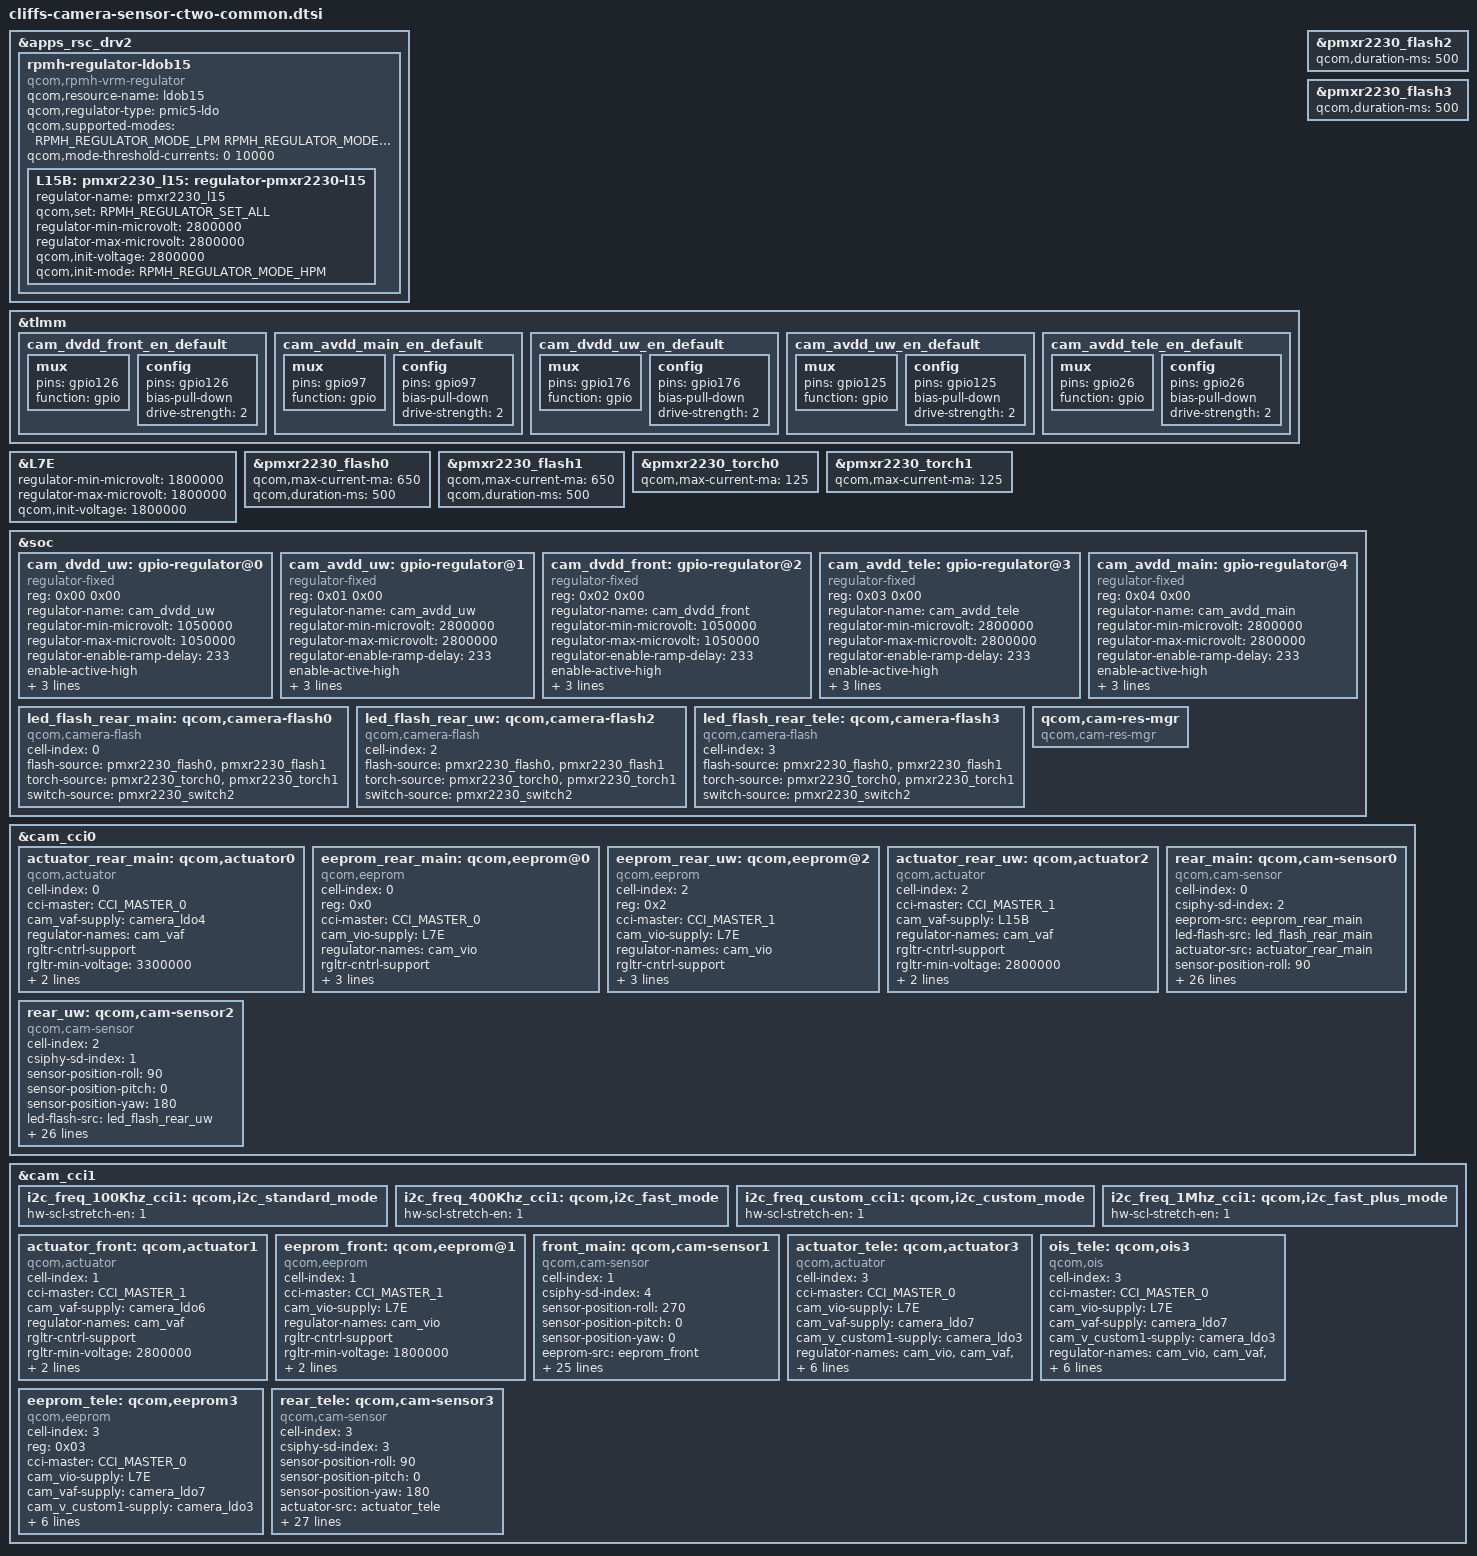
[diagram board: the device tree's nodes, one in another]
#include <dt-bindings/msm-camera.h>
#include <dt-bindings/regulator/qcom,rpmh-regulator-levels.h>

&apps_rsc_drv2 {
	rpmh-regulator-ldob15 {
		compatible = "qcom,rpmh-vrm-regulator";
		qcom,resource-name = "ldob15";
		qcom,regulator-type = "pmic5-ldo";
		qcom,supported-modes =
			<RPMH_REGULATOR_MODE_LPM
			RPMH_REGULATOR_MODE_HPM>;
		qcom,mode-threshold-currents = <0 10000>;

		L15B:
		pmxr2230_l15: regulator-pmxr2230-l15 {
			regulator-name = "pmxr2230_l15";
			qcom,set = <RPMH_REGULATOR_SET_ALL>;
			regulator-min-microvolt = <2800000>;
			regulator-max-microvolt = <2800000>;
			qcom,init-voltage = <2800000>;
			qcom,init-mode = <RPMH_REGULATOR_MODE_HPM>;
		};
	};
};

&tlmm {
	cam_dvdd_front_en_default: cam_dvdd_front_en_default {
		mux {
			pins = "gpio126";
			function = "gpio";
		};

		config {
			pins = "gpio126";
			bias-pull-down; /* PULL DOWN */
			drive-strength = <2>; /* 2 MA */
		};
	};

	cam_avdd_main_en_default: cam_avdd_main_en_default {
		mux {
			pins = "gpio97";
			function = "gpio";
		};

		config {
			pins = "gpio97";
			bias-pull-down; /* PULL DOWN */
			drive-strength = <2>; /* 2 MA */
		};
	};

	cam_dvdd_uw_en_default: cam_dvdd_uw_en_default {
		mux {
			pins = "gpio176";
			function = "gpio";
		};

		config {
			pins = "gpio176";
			bias-pull-down; /* PULL DOWN */
			drive-strength = <2>; /* 2 MA */
		};
	};

	cam_avdd_uw_en_default: cam_avdd_uw_en_default {
		mux {
			pins = "gpio125";
			function = "gpio";
		};

		config {
			pins = "gpio125";
			bias-pull-down; /* PULL DOWN */
			drive-strength = <2>; /* 2 MA */
		};
	};

	cam_avdd_tele_en_default: cam_avdd_tele_en_default {
		mux {
			pins = "gpio26";
			function = "gpio";
		};

		config {
			pins = "gpio26";
			bias-pull-down; /* PULL DOWN */
			drive-strength = <2>; /* 2 MA */
		};
	};

	//IOVDD for RON FVC
	//cam_iovdd_en_default: cam_iovdd_en_default {
	//	mux {
	//		pins = "gpio7";
	//		function = "gpio";
	//	};
	//
	//	config {
	//		pins = "gpio7";
	//		bias-pull-down; /* PULL DOWN */
	//		drive-strength = <2>; /* 2 MA */
	//	};
	//};

	//UW AFVDD for RON FVC
	//cam_afvdd_uw_en_default: cam_afvdd_uw_en_default {
	//	mux {
	//		pins = "gpio136";
	//		function = "gpio";
	//	};
	//
	//	config {
	//		pins = "gpio136";
	//		bias-pull-down; /* PULL DOWN */
	//		drive-strength = <2>; /* 2 MA */
	//	};
	//};
};

&L7E {
	regulator-min-microvolt = <1800000>;
	regulator-max-microvolt = <1800000>;
	qcom,init-voltage = <1800000>;
};

&pmxr2230_flash0 {
	qcom,max-current-ma = <650>;
	qcom,duration-ms = <500>;
};
&pmxr2230_flash1 {
	qcom,max-current-ma = <650>;
	qcom,duration-ms = <500>;
};
&pmxr2230_flash2 {
	qcom,duration-ms = <500>;
};
&pmxr2230_flash3 {
	qcom,duration-ms = <500>;
};

&pmxr2230_torch0 {
	qcom,max-current-ma = <125>;
};

&pmxr2230_torch1 {
	qcom,max-current-ma = <125>;
};

&soc {
	cam_dvdd_uw: gpio-regulator@0 {
		compatible = "regulator-fixed";
		reg = <0x00 0x00>;
		regulator-name = "cam_dvdd_uw";
		regulator-min-microvolt = <1050000>;
		regulator-max-microvolt = <1050000>;
		regulator-enable-ramp-delay = <233>;
		enable-active-high;
		gpio = <&tlmm 176 0>;
		pinctrl-names = "default";
		pinctrl-0 = <&cam_dvdd_uw_en_default>;
		vin-supply = <&S2B>;
	};

	cam_avdd_uw: gpio-regulator@1 {
		compatible = "regulator-fixed";
		reg = <0x01 0x00>;
		regulator-name = "cam_avdd_uw";
		regulator-min-microvolt = <2800000>;
		regulator-max-microvolt = <2800000>;
		regulator-enable-ramp-delay = <233>;
		enable-active-high;
		gpio = <&tlmm 125 0>;
		pinctrl-names = "default";
		pinctrl-0 = <&cam_avdd_uw_en_default>;
		vin-supply = <&BOB>;
	};

	cam_dvdd_front: gpio-regulator@2 {
		compatible = "regulator-fixed";
		reg = <0x02 0x00>;
		regulator-name = "cam_dvdd_front";
		regulator-min-microvolt = <1050000>;
		regulator-max-microvolt = <1050000>;
		regulator-enable-ramp-delay = <233>;
		enable-active-high;
		gpio = <&tlmm 126 0>;
		pinctrl-names = "default";
		pinctrl-0 = <&cam_dvdd_front_en_default>;
		vin-supply = <&S2B>;
	};

	cam_avdd_tele: gpio-regulator@3 {
		compatible = "regulator-fixed";
		reg = <0x03 0x00>;
		regulator-name = "cam_avdd_tele";
		regulator-min-microvolt = <2800000>;
		regulator-max-microvolt = <2800000>;
		regulator-enable-ramp-delay = <233>;
		enable-active-high;
		gpio = <&tlmm 26 0>;
		pinctrl-names = "default";
		pinctrl-0 = <&cam_avdd_tele_en_default>;
		vin-supply = <&BOB>;
	};

	cam_avdd_main: gpio-regulator@4 {
		compatible = "regulator-fixed";
		reg = <0x04 0x00>;
		regulator-name = "cam_avdd_main";
		regulator-min-microvolt = <2800000>;
		regulator-max-microvolt = <2800000>;
		regulator-enable-ramp-delay = <233>;
		enable-active-high;
		gpio = <&tlmm 97 0>;
		pinctrl-names = "default";
		pinctrl-0 = <&cam_avdd_main_en_default>;
		vin-supply = <&BOB>;
	};

/*
	//UW AFVDD for RON FVC
	cam_afvdd_uw: gpio-regulator@5 {
		compatible = "regulator-fixed";
		reg = <0x05 0x00>;
		regulator-name = "cam_afvdd_uw";
		regulator-min-microvolt = <2800000>;
		regulator-max-microvolt = <2800000>;
		regulator-enable-ramp-delay = <233>;
		enable-active-high;
		gpio = <&tlmm 136 0>;
		pinctrl-names = "default";
		pinctrl-0 = <&cam_afvdd_uw_en_default>;
		vin-supply = <&BOB>;
	};

	//IOVDD for RON FVC
	cam_iovdd: gpio-regulator@6 {
		compatible = "regulator-fixed";
		reg = <0x06 0x00>;
		regulator-name = "cam_iovdd";
		regulator-min-microvolt = <1800000>;
		regulator-max-microvolt = <1800000>;
		regulator-enable-ramp-delay = <233>;
		enable-active-high;
		gpio = <&tlmm 7 0>;
		pinctrl-names = "default";
		pinctrl-0 = <&cam_iovdd_en_default>;
		vin-supply = <&S1B>;
	};
*/

	led_flash_rear_main: qcom,camera-flash0 {
		cell-index = <0>;
		compatible = "qcom,camera-flash";
		flash-source = <&pmxr2230_flash0 &pmxr2230_flash1>;
		torch-source = <&pmxr2230_torch0 &pmxr2230_torch1>;
		switch-source = <&pmxr2230_switch2>;
		status = "ok";
	};

	led_flash_rear_uw: qcom,camera-flash2 {
		cell-index = <2>;
		compatible = "qcom,camera-flash";
		flash-source = <&pmxr2230_flash0 &pmxr2230_flash1>;
		torch-source = <&pmxr2230_torch0 &pmxr2230_torch1>;
		switch-source = <&pmxr2230_switch2>;
		status = "ok";
	};

	led_flash_rear_tele: qcom,camera-flash3 {
		cell-index = <3>;
		compatible = "qcom,camera-flash";
		flash-source = <&pmxr2230_flash0 &pmxr2230_flash1>;
		torch-source = <&pmxr2230_torch0 &pmxr2230_torch1>;
		switch-source = <&pmxr2230_switch2>;
		status = "ok";
	};

	qcom,cam-res-mgr {
		compatible = "qcom,cam-res-mgr";
		status = "ok";
	};
};

&cam_cci0 {
	actuator_rear_main: qcom,actuator0{
		cell-index = <0>;
		compatible = "qcom,actuator";
		cci-master = <CCI_MASTER_0>;
		cam_vaf-supply = <&camera_ldo4>;
		regulator-names = "cam_vaf";
		rgltr-cntrl-support;
		rgltr-min-voltage = <3300000>;
		rgltr-max-voltage = <3304000>;
		rgltr-load-current = <119000>;
		status = "ok";
	};

	eeprom_rear_main: qcom,eeprom@0 {
		cell-index = <0>;
		reg = <0x0>;
		compatible = "qcom,eeprom";
		cci-master = <CCI_MASTER_0>;
		cam_vio-supply = <&L7E>;
		regulator-names = "cam_vio";
		rgltr-cntrl-support;
		rgltr-min-voltage = <1800000>;
		rgltr-max-voltage = <1800000>;
		rgltr-load-current = <0>;
		status = "ok";
	};

 	eeprom_rear_uw: qcom,eeprom@2 {
		cell-index = <2>;
		reg = <0x2>;
		compatible = "qcom,eeprom";
		cci-master = <CCI_MASTER_1>;
		cam_vio-supply = <&L7E>;
		regulator-names = "cam_vio";
		rgltr-cntrl-support;
		rgltr-min-voltage = <1800000>;
		rgltr-max-voltage = <1800000>;
		rgltr-load-current = <0>;
		status = "ok";
	};

	actuator_rear_uw: qcom,actuator2{
		cell-index = <2>;
		compatible = "qcom,actuator";
		cci-master = <CCI_MASTER_1>;
		cam_vaf-supply = <&L15B>;
		regulator-names = "cam_vaf";
		rgltr-cntrl-support;
		rgltr-min-voltage = <2800000>;
		rgltr-max-voltage = <2800000>;
		rgltr-load-current = <147000>;
		status = "ok";
	};

	rear_main: qcom,cam-sensor0 {
		cell-index = <0>;
		compatible = "qcom,cam-sensor";
		csiphy-sd-index = <2>;
		eeprom-src = <&eeprom_rear_main>;
		led-flash-src = <&led_flash_rear_main>;
		actuator-src = <&actuator_rear_main>;
		sensor-position-roll = <90>;
		sensor-position-pitch = <0>;
		sensor-position-yaw = <180>;
		cam_vio-supply = <&L7E>;
		cam_vdig-supply = <&camera_ldo1>;
		cam_clk-supply = <&cam_cc_titan_top_gdsc>;
		cam_vana-supply = <&cam_avdd_main>;
		regulator-names = "cam_vana",
			"cam_vdig","cam_clk","cam_vio";
		rgltr-cntrl-support;
		rgltr-min-voltage = <2800000 1200000 0 1800000>;
		rgltr-max-voltage = <2800000 1200000 0 1800000>;
		rgltr-load-current = <101000 787000 0 1000>;
		gpio-no-mux = <0>;
		pinctrl-names = "cam_default", "cam_suspend";
		pinctrl-0 = <&cam_sensor_mclk0_active
			&cam_sensor_active_rst0>;
		pinctrl-1 = <&cam_sensor_mclk0_suspend
			&cam_sensor_suspend_rst0>;
		gpios = <&tlmm 64 0>,
			<&tlmm 15 0>;
		gpio-reset = <1>;
		gpio-req-tbl-num = <0 1>;
		gpio-req-tbl-flags = <1 0>;
		gpio-req-tbl-label = "CAMIF_MCLK0",
					"CAM_RESET0";
		cci-master = <CCI_MASTER_0>;
		clocks = <&camcc CAM_CC_MCLK0_CLK>;
		clock-names = "cam_clk";
		clock-cntl-level = "nominal";
		clock-rates = <19200000>;
		status = "ok";
	};

	rear_uw:qcom,cam-sensor2 {
		cell-index = <2>;
		compatible = "qcom,cam-sensor";
		csiphy-sd-index = <1>;
		sensor-position-roll = <90>;
		sensor-position-pitch = <0>;
		sensor-position-yaw = <180>;
		led-flash-src = <&led_flash_rear_uw>;
		eeprom-src = <&eeprom_rear_uw>;
		actuator-src = <&actuator_rear_uw>;
		cam_vio-supply = <&L7E>;
		cam_vdig-supply = <&cam_dvdd_uw>;
		cam_clk-supply = <&cam_cc_titan_top_gdsc>;
		cam_vana-supply = <&cam_avdd_uw>;
		regulator-names = "cam_vana",
			"cam_vdig", "cam_clk","cam_vio";
		rgltr-cntrl-support;
		rgltr-min-voltage = <2800000 1050000 0 1800000>;
		rgltr-max-voltage = <2800000 1050000 0 1800000>;
		rgltr-load-current = <148000 212000 0 3000>;
		gpio-no-mux = <0>;
		pinctrl-names = "cam_default", "cam_suspend";
		pinctrl-0 = <&cam_sensor_mclk1_active
				 &cam_sensor_active_rst1>;
		pinctrl-1 = <&cam_sensor_mclk1_suspend
				 &cam_sensor_suspend_rst1>;
		gpios = <&tlmm 65 0>,
			<&tlmm 14 0>;
		gpio-reset = <1>;
		gpio-req-tbl-num = <0 1>;
		gpio-req-tbl-flags = <1 0>;
		gpio-req-tbl-label = "CAMIF_MCLK1",
					"CAM_RESET1";
		cci-master = <CCI_MASTER_1>;
		clocks = <&camcc CAM_CC_MCLK1_CLK>;
		clock-names = "cam_clk";
		clock-cntl-level = "nominal";
		clock-rates = <24000000>;
		status = "ok";
	};
};

&cam_cci1 {
	i2c_freq_100Khz_cci1: qcom,i2c_standard_mode {
		hw-scl-stretch-en = <1>;
	};

	i2c_freq_400Khz_cci1: qcom,i2c_fast_mode {
		hw-scl-stretch-en = <1>;
	};

	i2c_freq_custom_cci1: qcom,i2c_custom_mode {
		hw-scl-stretch-en = <1>;
	};

	i2c_freq_1Mhz_cci1: qcom,i2c_fast_plus_mode {
		hw-scl-stretch-en = <1>;
	};

	actuator_front: qcom,actuator1{
		cell-index = <1>;
		compatible = "qcom,actuator";
		cci-master = <CCI_MASTER_1>;
		cam_vaf-supply = <&camera_ldo6>;
		regulator-names = "cam_vaf";
		rgltr-cntrl-support;
		rgltr-min-voltage = <2800000>;
		rgltr-max-voltage = <2800000>;
		rgltr-load-current = <95000>;
		status = "ok";
	};

	eeprom_front: qcom,eeprom@1 {
		cell-index = <1>;
		compatible = "qcom,eeprom";
		cci-master = <CCI_MASTER_1>;
		cam_vio-supply = <&L7E>;
		regulator-names = "cam_vio";
		rgltr-cntrl-support;
		rgltr-min-voltage = <1800000>;
		rgltr-max-voltage = <1800000>;
		rgltr-load-current = <3000>;
		status = "ok";
	};

	front_main: qcom,cam-sensor1 {
		cell-index = <1>;
		compatible = "qcom,cam-sensor";
		csiphy-sd-index = <4>;
		sensor-position-roll  = <270>;
		sensor-position-pitch = <0>;
		sensor-position-yaw   = <0>;
		eeprom-src = <&eeprom_front>;
		actuator-src = <&actuator_front>;
		cam_vio-supply  = <&L7E>;
		cam_vdig-supply = <&cam_dvdd_front>;
		cam_clk-supply  = <&cam_cc_titan_top_gdsc>;
		cam_vana-supply = <&camera_ldo5>;
		regulator-names = "cam_vdig", "cam_clk", "cam_vana","cam_vio";
		rgltr-cntrl-support;
		rgltr-min-voltage  = <1050000 0 2800000 1800000>;
		rgltr-max-voltage  = <1050000 0 2800000 1800000>;
		rgltr-load-current = <125000  0 95000   3000>;
		gpio-no-mux = <0>;
		pinctrl-names = "cam_default", "cam_suspend";
		pinctrl-0 = <&cam_sensor_mclk3_active &cam_sensor_active_rst3>;
		pinctrl-1 = <&cam_sensor_mclk3_suspend &cam_sensor_suspend_rst3>;
		gpios = <&tlmm 67 0>, <&tlmm 13 0>;
		gpio-reset = <1>;
		gpio-req-tbl-num   = <0 1>;
		gpio-req-tbl-flags = <1 0>;
		gpio-req-tbl-label = "CAMIF_MCLK3", "CAM_RESET3";
		cci-master = <CCI_MASTER_1>;
		clocks = <&camcc CAM_CC_MCLK3_CLK>;
		clock-names = "cam_clk";
		clock-cntl-level = "nominal";
		clock-rates = <24000000>;
		status = "ok";
	};

	actuator_tele: qcom,actuator3{
		cell-index = <3>;
		compatible = "qcom,actuator";
		cci-master = <CCI_MASTER_0>;
		cam_vio-supply = <&L7E>;
		cam_vaf-supply = <&camera_ldo7>;
		cam_v_custom1-supply = <&camera_ldo3>;
		regulator-names = "cam_vio", "cam_vaf", "cam_v_custom1";
		rgltr-cntrl-support;
		rgltr-min-voltage = <1800000 2800000 2800000>;
		rgltr-max-voltage = <1800000 2804000 2804000>;
		rgltr-load-current = <1000 227000 20000>;
		af-ois-use-same-ic;
		status = "ok";
	};

	ois_tele: qcom,ois3 {
		cell-index = <3>;
		compatible = "qcom,ois";
		cci-master = <CCI_MASTER_0>;
		cam_vio-supply = <&L7E>;
		cam_vaf-supply = <&camera_ldo7>;
		cam_v_custom1-supply  = <&camera_ldo3>;
		regulator-names = "cam_vio", "cam_vaf", "cam_v_custom1";
		rgltr-cntrl-support;
		rgltr-min-voltage = <1800000 2800000 2800000>;
		rgltr-max-voltage = <1800000 2804000 2804000>;
		rgltr-load-current = <1000 227000 20000>;
		af-ois-use-same-ic;
		status = "ok";
	};

	eeprom_tele: qcom,eeprom3 {
		cell-index = <3>;
		reg = <0x03>;
		compatible = "qcom,eeprom";
		cci-master = <CCI_MASTER_0>;
		cam_vio-supply = <&L7E>;
		cam_vaf-supply = <&camera_ldo7>;
		cam_v_custom1-supply  = <&camera_ldo3>;
		regulator-names = "cam_vio", "cam_vaf", "cam_v_custom1";
		rgltr-cntrl-support;
		rgltr-min-voltage = <1800000 2800000 2800000>;
		rgltr-max-voltage = <1800000 2804000 2804000>;
		rgltr-load-current = <1000 227000 20000>;
		status = "ok";
	};

	rear_tele:qcom,cam-sensor3 {
		cell-index = <3>;
		compatible = "qcom,cam-sensor";
		csiphy-sd-index = <3>;
		sensor-position-roll = <90>;
		sensor-position-pitch = <0>;
		sensor-position-yaw = <180>;
		actuator-src = <&actuator_tele>;
		ois-src = <&ois_tele>;
		eeprom-src = <&eeprom_tele>;
		led-flash-src = <&led_flash_rear_tele>;
		cam_vio-supply = <&L7E>;
		cam_vdig-supply = <&camera_ldo2>;
		cam_clk-supply = <&cam_cc_titan_top_gdsc>;
		cam_vana-supply = <&cam_avdd_tele>;
		regulator-names = "cam_vio", "cam_vdig",
			"cam_clk", "cam_vana";
		rgltr-cntrl-support;
		rgltr-min-voltage = <1800000 1100000 0 2800000>;
		rgltr-max-voltage = <1800000 1104000 0 2800000>;
		rgltr-load-current = <155000 680000 0 50000>;
		gpio-no-mux = <0>;
		pinctrl-names = "cam_default", "cam_suspend";
		pinctrl-0 = <&cam_sensor_mclk2_active
				 &cam_sensor_active_rst2>;
		pinctrl-1 = <&cam_sensor_mclk2_suspend
				 &cam_sensor_suspend_rst2>;
		gpios = <&tlmm 66 0>,
			<&tlmm 12 0>;
		gpio-reset = <1>;
		gpio-req-tbl-num = <0 1>;
		gpio-req-tbl-flags = <1 0>;
		gpio-req-tbl-label = "CAMIF_MCLK2",
					"CAM_RESET2";
		cci-master = <CCI_MASTER_0>;
		clocks = <&camcc CAM_CC_MCLK2_CLK>;
		clock-names = "cam_clk";
		clock-cntl-level = "nominal";
		clock-rates = <19200000>;
		status = "ok";
	};
};
